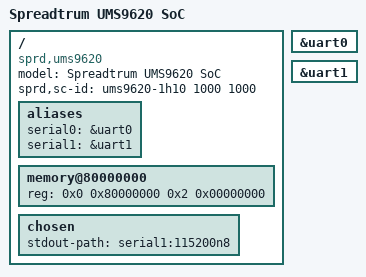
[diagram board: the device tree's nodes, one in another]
// SPDX-License-Identifier: GPL-2.0-only
/*
 * Unisoc Qogirn6pro platform DTS file
 *
 * Copyright (C) 2020, Unisoc Inc.
 */

/dts-v1/;

#include "ums9620-1h10.dtsi"
#include "ums9620-1h10-mach.dtsi"

/ {
	model = "Spreadtrum UMS9620 SoC";

	compatible = "sprd,ums9620";

	sprd,sc-id = "ums9620-1h10 1000 1000";

	aliases {
		serial0 = &uart0;
		serial1 = &uart1;
	};

	memory@80000000 {
		device_type = "memory";
		reg = <0x0 0x80000000 0x2 0x00000000>;
	};

	chosen: chosen {
		stdout-path = "serial1:115200n8";
	};
};

&uart0 {
	status = "okay";
};

&uart1 {
	status = "okay";
};
